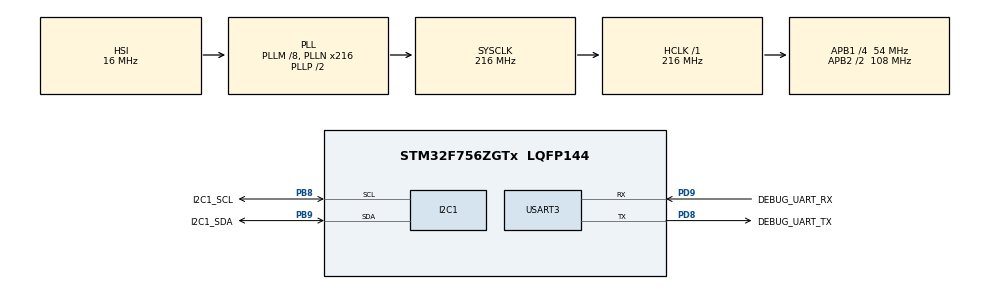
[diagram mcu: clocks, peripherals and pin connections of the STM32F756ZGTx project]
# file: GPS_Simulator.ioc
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FREERTOS.Queues01=gpsMsgQueue,16,gps_msg_t,0,Dynamic,NULL,NULL
FREERTOS.Tasks01=defaultTask,32,256,StartDefaultTask,Default,NULL,Dynamic,NULL,NULL;GPSTask,24,256,StartGPSTask,As weak,NULL,Dynamic,NULL,NULL;I2CSenderTask,25,256,StartI2CSenderTask,As weak,NULL,Dynamic,NULL,NULL
FREERTOS.configUSE_NEWLIB_REENTRANT=1
I2C1.OwnAddress=0x10
I2C1.Timing=0x20404768
Mcu.Family=STM32F7
Mcu.Name=STM32F756ZGTx
Mcu.Package=LQFP144
NVIC.I2C1_ER_IRQn=true\:5\:0\:false\:false\:true\:true\:true\:true\:true
NVIC.I2C1_EV_IRQn=true\:5\:0\:false\:false\:true\:true\:true\:true\:true
NVIC.PriorityGroup=NVIC_PRIORITYGROUP_4
NVIC.TIM6_DAC_IRQn=true\:15\:0\:false\:false\:true\:false\:false\:true\:true
NVIC.TIM7_IRQn=true\:5\:0\:false\:false\:true\:true\:true\:true\:true
NVIC.TimeBase=TIM6_DAC_IRQn
NVIC.TimeBaseIP=TIM6
PA13.Mode=Serial_Wire
PA13.Signal=SYS_JTMS-SWDIO
PA14.Mode=Serial_Wire
PA14.Signal=SYS_JTCK-SWCLK
PB8.GPIO_Label=I2C1_SCL
PB8.GPIO_Pu=GPIO_PULLUP
PB8.Mode=I2C
PB8.Signal=I2C1_SCL
PB9.GPIO_Label=I2C1_SDA
PB9.GPIO_Pu=GPIO_PULLUP
PB9.Mode=I2C
PB9.Signal=I2C1_SDA
PD8.GPIO_Label=DEBUG_UART_TX
PD8.Mode=Asynchronous
PD8.Signal=USART3_TX
PD9.GPIO_Label=DEBUG_UART_RX
PD9.Mode=Asynchronous
PD9.Signal=USART3_RX
ProjectManager.HeapSize=0x200
ProjectManager.StackSize=0x400
ProjectManager.TargetToolchain=STM32CubeIDE
RCC.AHBFreq_Value=216000000
RCC.APB1CLKDivider=RCC_HCLK_DIV4
RCC.APB1Freq_Value=54000000
RCC.APB1TimFreq_Value=108000000
RCC.APB2CLKDivider=RCC_HCLK_DIV2
RCC.APB2Freq_Value=108000000
RCC.APB2TimFreq_Value=216000000
RCC.CortexFreq_Value=216000000
RCC.HCLKFreq_Value=216000000
RCC.HSE_VALUE=25000000
RCC.HSI_VALUE=16000000
RCC.LSE_VALUE=32768
RCC.PLLM=8
RCC.PLLN=216
RCC.SYSCLKFreq_VALUE=216000000
RCC.SYSCLKSource=RCC_SYSCLKSOURCE_PLLCLK
RCC.USBFreq_Value=216000000
RCC.VCOOutputFreq_Value=432000000
TIM7.Period=10000-1
TIM7.Prescaler=10800-1
TIM7.TIM_MasterOutputTrigger=TIM_TRGO_UPDATE
USART3.VirtualMode-Asynchronous=VM_ASYNC
VP_FREERTOS_VS_CMSIS_V2.Mode=CMSIS_V2
VP_SYS_VS_tim6.Mode=TIM6
VP_TIM7_VS_ClockSourceINT.Mode=Enable_Timer
board=custom

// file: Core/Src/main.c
/* USER CODE BEGIN Header */
/**
  ******************************************************************************
  * @file           : main.c
  * @brief          : Main program body
  ******************************************************************************
  * @attention
  *
  * Copyright (c) 2025 STMicroelectronics.
  * All rights reserved.
  *
  * This software is licensed under terms that can be found in the LICENSE file
  * in the root directory of this software component.
  * If no LICENSE file comes with this software, it is provided AS-IS.
  *
  ******************************************************************************
  */
/* USER CODE END Header */
#include "main.h"
#include "cmsis_os.h"

/* USER CODE BEGIN Includes */
#include "gps_sim.h"
/* USER CODE END Includes */

I2C_HandleTypeDef hi2c1;

TIM_HandleTypeDef htim7;

UART_HandleTypeDef huart3;

/* Definitions for defaultTask */
osThreadId_t defaultTaskHandle;
const osThreadAttr_t defaultTask_attributes = {
  .name = "defaultTask",
  .stack_size = 256 * 4,
  .priority = (osPriority_t) osPriorityAboveNormal,
};
/* Definitions for GPSTask */
osThreadId_t GPSTaskHandle;
const osThreadAttr_t GPSTask_attributes = {
  .name = "GPSTask",
  .stack_size = 256 * 4,
  .priority = (osPriority_t) osPriorityNormal,
};
/* Definitions for I2CSenderTask */
osThreadId_t I2CSenderTaskHandle;
const osThreadAttr_t I2CSenderTask_attributes = {
  .name = "I2CSenderTask",
  .stack_size = 256 * 4,
  .priority = (osPriority_t) osPriorityNormal1,
};
/* Definitions for gpsMsgQueue */
osMessageQueueId_t gpsMsgQueueHandle;
const osMessageQueueAttr_t gpsMsgQueue_attributes = {
  .name = "gpsMsgQueue"
};
/* USER CODE BEGIN PV */
extern volatile uint32_t utc_seconds;
/* USER CODE END PV */

void SystemClock_Config(void);
static void MX_GPIO_Init(void);
static void MX_I2C1_Init(void);
static void MX_USART3_UART_Init(void);
static void MX_TIM7_Init(void);
void StartDefaultTask(void *argument);
void StartGPSTask(void *argument);
void StartI2CSenderTask(void *argument);

/* USER CODE BEGIN 0 */
int __io_putchar(int ch) {
	HAL_UART_Transmit(&huart3, (uint8_t*) &ch, 1, 0xFFFF);
	return ch;
}

int _write(int file, char *ptr, int len) {
	char *cr = "\r";
	HAL_UART_Transmit(&huart3, (uint8_t*) ptr, len, 0xFFFF);
	HAL_UART_Transmit(&huart3, (uint8_t*) cr, 1, 0xFFFF);
	return len + 1;
}
/* USER CODE END 0 */

int main(void)
{

  /* MCU Configuration--------------------------------------------------------*/

  /* Reset of all peripherals, Initializes the Flash interface and the Systick. */
  HAL_Init();

  /* Configure the system clock */
  SystemClock_Config();

  /* Initialize all configured peripherals */
  MX_GPIO_Init();
  MX_I2C1_Init();
  MX_USART3_UART_Init();
  MX_TIM7_Init();
  /* USER CODE BEGIN 2 */
  HAL_TIM_Base_Start_IT(&htim7);
  /* USER CODE END 2 */

  /* Init scheduler */
  osKernelInitialize();

  /* Create the queue(s) */
  /* creation of gpsMsgQueue */
  gpsMsgQueueHandle = osMessageQueueNew (16, sizeof(gps_msg_t), &gpsMsgQueue_attributes);

  /* Create the thread(s) */
  /* creation of defaultTask */
  defaultTaskHandle = osThreadNew(StartDefaultTask, NULL, &defaultTask_attributes);

  /* creation of GPSTask */
  GPSTaskHandle = osThreadNew(StartGPSTask, NULL, &GPSTask_attributes);

  /* creation of I2CSenderTask */
  I2CSenderTaskHandle = osThreadNew(StartI2CSenderTask, NULL, &I2CSenderTask_attributes);

  /* Start scheduler */
  osKernelStart();

  /* We should never get here as control is now taken by the scheduler */

  /* Infinite loop */
  while (1)
  {

  }
}

void SystemClock_Config(void)
{
  RCC_OscInitTypeDef RCC_OscInitStruct = {0};
  RCC_ClkInitTypeDef RCC_ClkInitStruct = {0};

  /** Configure the main internal regulator output voltage
  */
  __HAL_RCC_PWR_CLK_ENABLE();
  __HAL_PWR_VOLTAGESCALING_CONFIG(PWR_REGULATOR_VOLTAGE_SCALE1);

  /** Initializes the RCC Oscillators according to the specified parameters
  * in the RCC_OscInitTypeDef structure.
  */
  RCC_OscInitStruct.OscillatorType = RCC_OSCILLATORTYPE_HSI;
  RCC_OscInitStruct.HSIState = RCC_HSI_ON;
  RCC_OscInitStruct.HSICalibrationValue = RCC_HSICALIBRATION_DEFAULT;
  RCC_OscInitStruct.PLL.PLLState = RCC_PLL_ON;
  RCC_OscInitStruct.PLL.PLLSource = RCC_PLLSOURCE_HSI;
  RCC_OscInitStruct.PLL.PLLM = 8;
  RCC_OscInitStruct.PLL.PLLN = 216;
  RCC_OscInitStruct.PLL.PLLP = RCC_PLLP_DIV2;
  RCC_OscInitStruct.PLL.PLLQ = 2;
  if (HAL_RCC_OscConfig(&RCC_OscInitStruct) != HAL_OK)
  {
    Error_Handler();
  }

  /** Activate the Over-Drive mode
  */
  if (HAL_PWREx_EnableOverDrive() != HAL_OK)
  {
    Error_Handler();
  }

  /** Initializes the CPU, AHB and APB buses clocks
  */
  RCC_ClkInitStruct.ClockType = RCC_CLOCKTYPE_HCLK|RCC_CLOCKTYPE_SYSCLK
                              |RCC_CLOCKTYPE_PCLK1|RCC_CLOCKTYPE_PCLK2;
  RCC_ClkInitStruct.SYSCLKSource = RCC_SYSCLKSOURCE_PLLCLK;
  RCC_ClkInitStruct.AHBCLKDivider = RCC_SYSCLK_DIV1;
  RCC_ClkInitStruct.APB1CLKDivider = RCC_HCLK_DIV4;
  RCC_ClkInitStruct.APB2CLKDivider = RCC_HCLK_DIV2;

  if (HAL_RCC_ClockConfig(&RCC_ClkInitStruct, FLASH_LATENCY_7) != HAL_OK)
  {
    Error_Handler();
  }
}

static void MX_I2C1_Init(void)
{

  hi2c1.Instance = I2C1;
  hi2c1.Init.Timing = 0x20404768;
  hi2c1.Init.OwnAddress1 = 32;
  hi2c1.Init.AddressingMode = I2C_ADDRESSINGMODE_7BIT;
  hi2c1.Init.DualAddressMode = I2C_DUALADDRESS_DISABLE;
  hi2c1.Init.OwnAddress2 = 0;
  hi2c1.Init.OwnAddress2Masks = I2C_OA2_NOMASK;
  hi2c1.Init.GeneralCallMode = I2C_GENERALCALL_DISABLE;
  hi2c1.Init.NoStretchMode = I2C_NOSTRETCH_DISABLE;
  if (HAL_I2C_Init(&hi2c1) != HAL_OK)
  {
    Error_Handler();
  }

  /** Configure Analogue filter
  */
  if (HAL_I2CEx_ConfigAnalogFilter(&hi2c1, I2C_ANALOGFILTER_ENABLE) != HAL_OK)
  {
    Error_Handler();
  }

  /** Configure Digital filter
  */
  if (HAL_I2CEx_ConfigDigitalFilter(&hi2c1, 0) != HAL_OK)
  {
    Error_Handler();
  }

}

static void MX_TIM7_Init(void)
{

  TIM_MasterConfigTypeDef sMasterConfig = {0};

  htim7.Instance = TIM7;
  htim7.Init.Prescaler = 10800-1;
  htim7.Init.CounterMode = TIM_COUNTERMODE_UP;
  htim7.Init.Period = 10000-1;
  htim7.Init.AutoReloadPreload = TIM_AUTORELOAD_PRELOAD_DISABLE;
  if (HAL_TIM_Base_Init(&htim7) != HAL_OK)
  {
    Error_Handler();
  }
  sMasterConfig.MasterOutputTrigger = TIM_TRGO_UPDATE;
  sMasterConfig.MasterSlaveMode = TIM_MASTERSLAVEMODE_DISABLE;
  if (HAL_TIMEx_MasterConfigSynchronization(&htim7, &sMasterConfig) != HAL_OK)
  {
    Error_Handler();
  }

}

static void MX_USART3_UART_Init(void)
{

  huart3.Instance = USART3;
  huart3.Init.BaudRate = 115200;
  huart3.Init.WordLength = UART_WORDLENGTH_8B;
  huart3.Init.StopBits = UART_STOPBITS_1;
  huart3.Init.Parity = UART_PARITY_NONE;
  huart3.Init.Mode = UART_MODE_TX_RX;
  huart3.Init.HwFlowCtl = UART_HWCONTROL_NONE;
  huart3.Init.OverSampling = UART_OVERSAMPLING_16;
  huart3.Init.OneBitSampling = UART_ONE_BIT_SAMPLE_DISABLE;
  huart3.AdvancedInit.AdvFeatureInit = UART_ADVFEATURE_NO_INIT;
  if (HAL_UART_Init(&huart3) != HAL_OK)
  {
    Error_Handler();
  }

}

static void MX_GPIO_Init(void)
{

  /* GPIO Ports Clock Enable */
  __HAL_RCC_GPIOD_CLK_ENABLE();
  __HAL_RCC_GPIOA_CLK_ENABLE();
  __HAL_RCC_GPIOB_CLK_ENABLE();

}

void StartDefaultTask(void *argument)
{
  for(;;)
  {
    osDelay(1);
  }
}

__weak void StartGPSTask(void *argument)
{
  for(;;)
  {
    osDelay(1);
  }
}

__weak void StartI2CSenderTask(void *argument)
{
  for(;;)
  {
    osDelay(1);
  }
}

void HAL_TIM_PeriodElapsedCallback(TIM_HandleTypeDef *htim)
{
  if (htim->Instance == TIM6)
  {
    HAL_IncTick();
  }
  /* USER CODE BEGIN Callback 1 */
  if (htim->Instance == TIM7)
  {
    utc_seconds++;
  }
  /* USER CODE END Callback 1 */
}

void Error_Handler(void)
{
  __disable_irq();
  while (1)
  {
  }
}
